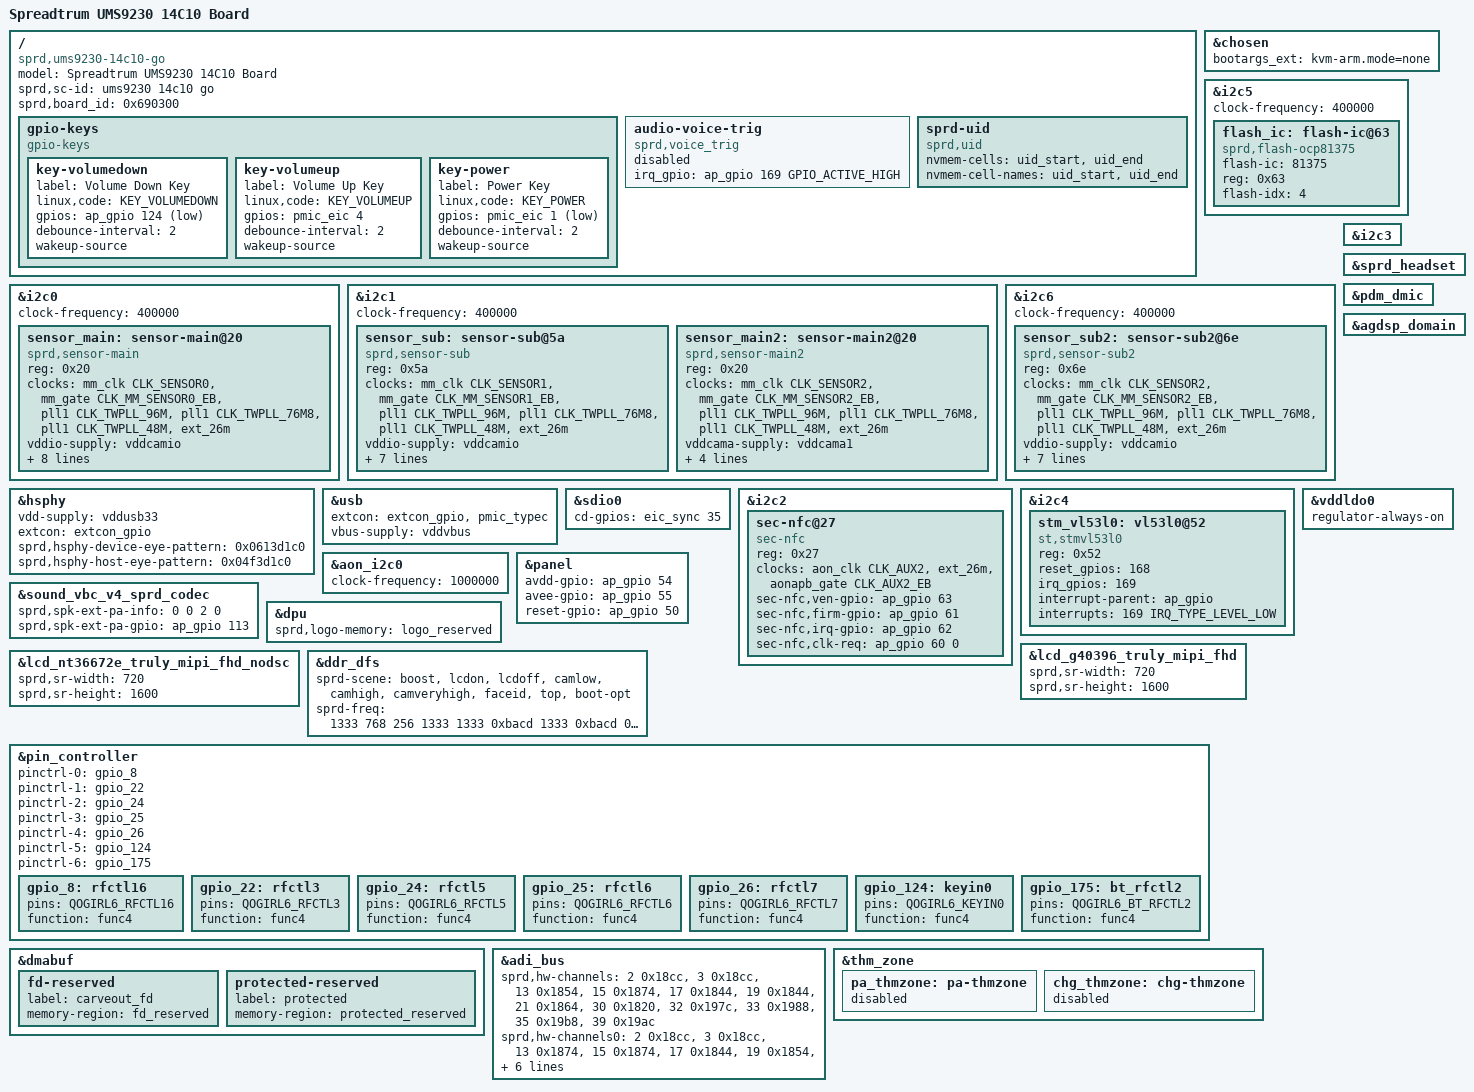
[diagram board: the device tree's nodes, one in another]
// SPDX-License-Identifier: GPL-2.0-only
/*
 * Spreadtrum Qogirl6 board common DTS file
 *
 * Copyright (C) 2021, Unisoc Inc.
 */

/dts-v1/;
/plugin/;
#include <dt-bindings/input/input.h>
#include <dt-bindings/gpio/gpio.h>
#include <dt-bindings/interrupt-controller/arm-gic.h>
#include <dt-bindings/clock/sprd,ums9230-clk.h>
#include <dt-bindings/mfd/sprd,sc2730-regs.h>
#include <dt-bindings/mfd/sprd,sc2730-mask.h>
#include <dt-bindings/usb/pd.h>
#include "lcd/lcd_nt36528_boe_mipi_hdp.dtsi"
#include "lcd/lcd_g40396_truly_mipi_fhd.dtsi"
#include "lcd/lcd_nt36672e_truly_mipi_fhd_nodsc.dtsi"
//#include "lcd/lcd_nt36672e_truly_mipi_fhd.dtsi"
#include "lcd/lcd_dummy_mipi.dtsi"
#include "touchscreen/ums9230-14c10-spi3-eic16-gpio145-tp.dtsi"
#include "battery/ums9230-14c10-go-overlay.dtsi"
#include "reserved-memory/ums9230-14c10-go-overlay.dtsi"
#include "ums9230/wcn.dtsi"
#include "wcn/wcn_modules.h"
#include "wcn/chip/wcn-integrate-sharkl6-register.dtsi"

/ {

	model = "Spreadtrum UMS9230 14C10 Board";

	compatible = "sprd,ums9230-14c10-go";

	sprd,sc-id = "ums9230 14c10 go";

	sprd,board_id = <0x690300>; //XXYY00:base board,XXYY00~XXYYFF:customize board

	fragment {
		target-path = "/";
		__overlay__ {
			/*fingerprint@0 {
				compatible = "microarray,afs121";
				fpint-gpios = <&eic_async 29 0>;
			};*/

			gpio-keys {
				compatible = "gpio-keys";

				key-volumedown {
					label = "Volume Down Key";
					linux,code = <KEY_VOLUMEDOWN>;
					gpios = <&ap_gpio 124 GPIO_ACTIVE_LOW>;
					debounce-interval = <2>;
					wakeup-source;
				};

				key-volumeup {
					label = "Volume Up Key";
					linux,code = <KEY_VOLUMEUP>;
					gpios = <&pmic_eic 4 GPIO_ACTIVE_HIGH>;
					debounce-interval = <2>;
					wakeup-source;
				};

				key-power {
					label = "Power Key";
					linux,code = <KEY_POWER>;
					gpios = <&pmic_eic 1 GPIO_ACTIVE_LOW>;
					debounce-interval = <2>;
					wakeup-source;
				};
			};

			audio-voice-trig {
				status = "disable";
				compatible = "sprd,voice_trig";
				irq_gpio = <&ap_gpio 169 GPIO_ACTIVE_HIGH>;
			};

			sprd-uid {
				compatible = "sprd,uid";
				nvmem-cells = <&uid_start>, <&uid_end>;
				nvmem-cell-names = "uid_start", "uid_end";
			};

		};
	};
};

&chosen {
	bootargs_ext = "kvm-arm.mode=none";
};

&i2c0 {
	status = "okay";
	clock-frequency = <400000>;
	#address-cells = <1>;
	#size-cells = <0>;

	sensor_main: sensor-main@20 {
		compatible = "sprd,sensor-main";
		reg = <0x20>;
		clock-names = "clk_src","sensor_eb",
			"clk_96m","clk_76m8",
			"clk_48m","clk_26m";
		clocks = <&mm_clk CLK_SENSOR0>,<&mm_gate CLK_MM_SENSOR0_EB>,
				<&pll1 CLK_TWPLL_96M>,<&pll1 CLK_TWPLL_76M8>,
				<&pll1 CLK_TWPLL_48M>,<&ext_26m>;
		vddio-supply = <&vddcamio>;
		vddcama-supply = <&vddcama0>;
		vddcamd-supply = <&vddcamd0>;
		vddcammot-supply = <&vddcammot>;
		reset-gpios = <&ap_gpio 44 0>;
		power-down-gpios = <&ap_gpio 46 0>;
		sprd,phyid = <2>;
		csi = <&csi0>;
		power-domains = <&mm_domain>;
	};
};

&i2c1 {
	status = "okay";
	clock-frequency = <400000>;
	#address-cells = <1>;
	#size-cells = <0>;

	sensor_sub: sensor-sub@5a {
		compatible = "sprd,sensor-sub";
		reg = <0x5a>;
		clock-names = "clk_src","sensor_eb",
			"clk_96m","clk_76m8",
			"clk_48m","clk_26m";
		clocks = <&mm_clk CLK_SENSOR1>,<&mm_gate CLK_MM_SENSOR1_EB>,
				<&pll1 CLK_TWPLL_96M>,<&pll1 CLK_TWPLL_76M8>,
				<&pll1 CLK_TWPLL_48M>,<&ext_26m>;
		vddio-supply = <&vddcamio>;
		vddcama-supply = <&vddcama1>;
		vddcamd-supply = <&vddcamd1>;
		reset-gpios = <&ap_gpio 41 0>;
		power-down-gpios = <&ap_gpio 40 0>;
		/* mipi-switch-en-gpios = <&ap_gpio 55 0>; */
		/* mipi-switch-mode-gpios = <&ap_gpio 8 0>; */
		sprd,phyid = <0>;
		csi = <&csi1>;
		power-domains = <&mm_domain>;
	};

	sensor_main2: sensor-main2@20 {
		compatible = "sprd,sensor-main2";
		reg = <0x20>;
		clock-names = "clk_src","sensor_eb",
			"clk_96m","clk_76m8",
			"clk_48m","clk_26m";
		clocks = <&mm_clk CLK_SENSOR2>,<&mm_gate CLK_MM_SENSOR2_EB>,
				<&pll1 CLK_TWPLL_96M>,<&pll1 CLK_TWPLL_76M8>,
				<&pll1 CLK_TWPLL_48M>,<&ext_26m>;
		vddcama-supply = <&vddcama1>;
		/* power-down-gpios = <&ap_gpio 47 0>; */
		fakeserial-gpios = <&ap_gpio 126 0>;
		/* mipi-switch-en-gpios = <&ap_gpio 55 0>; */
		/* mipi-switch-mode-gpios = <&ap_gpio 8 0>; */
		sprd,phyid = <3>;
		csi = <&csi2>;
		power-domains = <&mm_domain>;
	};


};

&i2c5 {
	status = "okay";
	clock-frequency = <400000>;

	flash_ic: flash-ic@63 {
		compatible = "sprd,flash-ocp81375";
		flash-ic = <81375>;
		reg = <0x63>;
		/* flash-idx usage: */
		/* 1: LED1 used for back, LED2 not installed; */
		/* 2: LED1 used for front, LED2 not installed; */
		/* 3: LED1 used for back, LED2 used for front; */
		/* 4: LED1 used for front, LED2 used for back; */
		/* 5: LED1 and LED2 used for back; */
		/* 6: LED1 and LED2 used for front; */
		/* 7: LED2 used for back, LED1 not installed; */
		/* 8: LED2 used for front,LED1 not installed; */
		flash-idx = <4>;
	};
};

&i2c6 {
	status = "okay";
	clock-frequency = <400000>;
	#address-cells = <1>;
	#size-cells = <0>;

	sensor_sub2: sensor-sub2@6e {
		compatible = "sprd,sensor-sub2";
		reg = <0x6e>;
		clock-names = "clk_src","sensor_eb",
			"clk_96m","clk_76m8",
			"clk_48m","clk_26m";
		clocks = <&mm_clk CLK_SENSOR2>,<&mm_gate CLK_MM_SENSOR2_EB>,
			<&pll1 CLK_TWPLL_96M>,<&pll1 CLK_TWPLL_76M8>,
			<&pll1 CLK_TWPLL_48M>,<&ext_26m>;
		vddio-supply = <&vddcamio>;
		avdd-gpios = <&ap_gpio 130 0>;
		vddcamd-supply = <&vddcamd1>;
		vddcammot-supply = <&vddcammot>;
		mot-gpios = <&ap_gpio 112 0>;
		reset-gpios = <&ap_gpio 114 0>;
	/*	power-down-gpios = <&ap_gpio 40 0>;*/
		sprd,phyid = <3>;
		csi = <&csi2>;
	};
};

&hsphy {
	vdd-supply = <&vddusb33>;
	extcon = <&extcon_gpio>;
	sprd,hsphy-device-eye-pattern = <0x0613d1c0>;
	sprd,hsphy-host-eye-pattern = <0x04f3d1c0>;
	status = "okay";
};

&usb {
	extcon = <&extcon_gpio>, <&pmic_typec>;
	vbus-supply = <&vddvbus>;
	status = "okay";
};

&sdio0 {
	cd-gpios = <&eic_sync 35 GPIO_ACTIVE_HIGH>;
};

&i2c2 {
	status = "okay";
	#address-cells = <1>;
	#size-cells = <0>;
	sec-nfc@27 {
		compatible = "sec-nfc";
		reg = <0x27>;
		clock-names = "nfc_clk","source","enable";
		clocks = <&aon_clk CLK_AUX2>, <&ext_26m>, <&aonapb_gate CLK_AUX2_EB>;
		sec-nfc,ven-gpio = <&ap_gpio 63 0>;
		sec-nfc,firm-gpio = <&ap_gpio 61 0>;
		sec-nfc,irq-gpio = <&ap_gpio 62 0>;
		sec-nfc,clk-req = <&ap_gpio 60 0>;
	};
};

&i2c3 {
	status = "okay";
	#address-cells = <1>;
	#size-cells = <0>;
};

&i2c4 {
	status = "okay";
	#address-cells = <1>;
	#size-cells = <0>;

	stm_vl53l0: vl53l0@52 {
		compatible = "st,stmvl53l0";
		reg = <0x52>;
		reset_gpios = <168>;
		irq_gpios = <169>;
		interrupt-parent = <&ap_gpio>;
		interrupts = <169 IRQ_TYPE_LEVEL_LOW>;
	};
};

&aon_i2c0 {
	status = "okay";
	clock-frequency = <1000000>;
};

&sprd_headset {
	status = "okay";
};

&pdm_dmic {
	status = "okay";
};

&agdsp_domain {
	status = "okay";
};

&sound_vbc_v4_sprd_codec {
	status = "okay";

	/* ext_control_type, hook selection, mode, gpio share */
	sprd,spk-ext-pa-info = <0 0 2 0>;
	sprd,spk-ext-pa-gpio = <&ap_gpio 113 GPIO_ACTIVE_HIGH>;
};

&vddldo0 {
	regulator-always-on;
};

&panel {
	//sprd,backlight = <&pwm_backlight>;
	avdd-gpio = <&ap_gpio 54 GPIO_ACTIVE_HIGH>;
	avee-gpio = <&ap_gpio 55 GPIO_ACTIVE_HIGH>;
	reset-gpio = <&ap_gpio 50 GPIO_ACTIVE_HIGH>;
};

&dpu {
	sprd,logo-memory = <&logo_reserved>;

	//sprd,backlight = <&pwm_backlight>;
};

&lcd_g40396_truly_mipi_fhd {
	sprd,sr-width = <720>;
	sprd,sr-height = <1600>;
};

&lcd_nt36672e_truly_mipi_fhd_nodsc {
	sprd,sr-width = <720>;
	sprd,sr-height = <1600>;
};

&ddr_dfs {
	  sprd-scene = "boost", "lcdon", "lcdoff", "camlow",
			"camhigh", "camveryhigh", "faceid", "top", "boot-opt";
	  sprd-freq = <1333 768 256 1333 1333 0xbacd 1333 0xbacd 0xbacd>;
};

&pin_controller {
	pinctrl-names =
	/* rfctl16 ,rfctl3, rfctl5 */
	"gpio_8", "gpio_22", "gpio_24",
	/* rfctl6, rfctl7, keyin0 */
	"gpio_25", "gpio_26", "gpio_124",
	/* bt_rfctl2 */
	"gpio_175";
	pinctrl-0 = <&gpio_8>;
	pinctrl-1 = <&gpio_22>;
	pinctrl-2 = <&gpio_24>;
	pinctrl-3 = <&gpio_25>;
	pinctrl-4 = <&gpio_26>;
	pinctrl-5 = <&gpio_124>;
	pinctrl-6 = <&gpio_175>;

	gpio_8: rfctl16 {
		pins = "QOGIRL6_RFCTL16";
		function = "func4";
	};

	gpio_22: rfctl3 {
		pins = "QOGIRL6_RFCTL3";
		function = "func4";
	};

	gpio_24: rfctl5 {
		pins = "QOGIRL6_RFCTL5";
		function = "func4";
	};

	gpio_25: rfctl6 {
		pins = "QOGIRL6_RFCTL6";
		function = "func4";
	};

	gpio_26: rfctl7 {
		pins = "QOGIRL6_RFCTL7";
		function = "func4";
	};

	gpio_124: keyin0 {
		pins = "QOGIRL6_KEYIN0";
		function = "func4";
	};

	gpio_175: bt_rfctl2 {
		pins = "QOGIRL6_BT_RFCTL2";
		function = "func4";
	};
};

&dmabuf {

	fd-reserved {
		label = "carveout_fd";
		memory-region = <&fd_reserved>;
	};

	protected-reserved {
		label = "protected";
		memory-region = <&protected_reserved>;
	};
};

&adi_bus {
	sprd,hw-channels = <2 0x18cc>, <3 0x18cc>, <13 0x1854>, <15 0x1874>,
			<17 0x1844>, <19 0x1844>, <21 0x1864>, <30 0x1820>,
			<32 0x197c>, <33 0x1988>, <35 0x19b8>, <39 0x19ac>;
	sprd,hw-channels0 = <2 0x18cc>, <3 0x18cc>, <13 0x1874>, <15 0x1874>,
			<17 0x1844>, <19 0x1854>, <21 0x1864>, <30 0x1820>,
			<32 0x197c>, <33 0x1988>, <35 0x19b8>, <39 0x19ac>;
	sprd,hw-channels1 = <2 0x18cc>, <3 0x18cc>, <13 0x1854>, <15 0x1874>,
			<17 0x1844>, <19 0x1844>, <21 0x1864>, <30 0x1820>,
			<32 0x197c>, <33 0x1988>, <35 0x19b8>, <39 0x19ac>;
};

&thm_zone {
	pa_thmzone: pa-thmzone {
		status = "disabled";
	};
};

&thm_zone {
	chg_thmzone: chg-thmzone {
		status = "disabled";
	};
};
